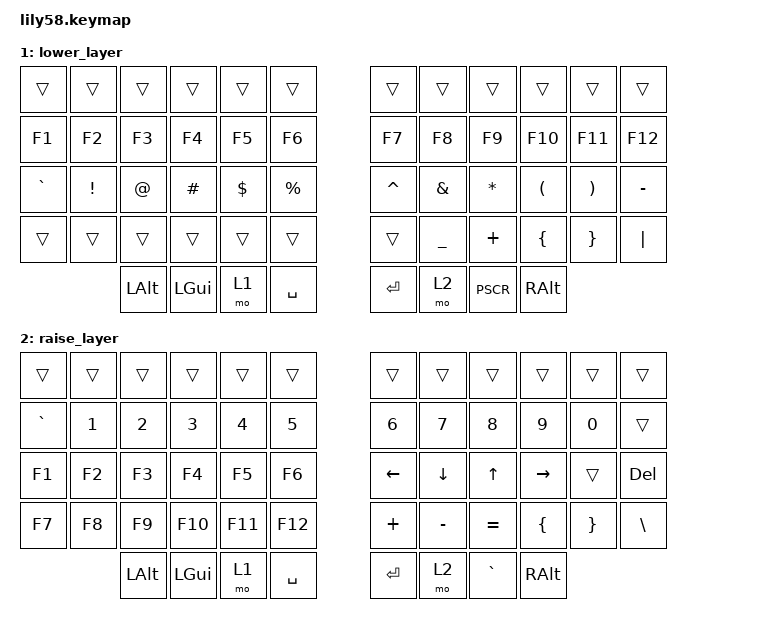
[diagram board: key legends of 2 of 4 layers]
/*
 * Copyright (c) 2020 The ZMK Contributors
 *
 * SPDX-License-Identifier: MIT
 */

#include <behaviors.dtsi>
#include <dt-bindings/zmk/keys.h>
#include <dt-bindings/zmk/bt.h>
#include <dt-bindings/zmk/ext_power.h>
#include <dt-bindings/zmk/rgb.h>

/ {
    // Activar la capa ADJUST presionando raise y lower
    conditional_layers {
        compatible = "zmk,conditional-layers";

        raise_layer {
            if-layers = <1>;
            then-layer = <3>;
        };

        lower_layer {
            if-layers = <2>;
            then-layer = <3>;
        };

        adjust_layer {
            if-layers = <1 2>;
            then-layer = <3>;
        };
    };

    keymap {
        compatible = "zmk,keymap";

        default_layer {
            /* default_layer
             * ,-----------------------------------------.                    ,-----------------------------------------.
             * | ESC  |   1  |   2  |   3  |   4  |   5  |                    |   6  |   7  |   8  |   9  |   0  |BackSP|
             * |------+------+------+------+------+------|                    |------+------+------+------+------+------|
             * | Tab  |   Q  |   W  |   E  |   R  |   T  |                    |   Y  |   U  |   I  |   O  |   P  |  -   |
             * |------+------+------+------+------+------|                    |------+------+------+------+------+------|
             * |LShift|   A  |   S  |   D  |   F  |   G  |-------.    ,-------|   H  |   J  |   K  |   L  |   ;  |  '   |
             * |------+------+------+------+------+------|   [   |    |    ]  |------+------+------+------+------+------|
             * |LCTRL |   Z  |   X  |   C  |   V  |   B  |-------|    |-------|   N  |   M  |   ,  |   .  |   /  |RShift|
             * `-----------------------------------------/       /     \      \-----------------------------------------'
             *                   | LAlt | LGUI |LOWER | /Space  /       \Enter \  |RAISE |  `   | RALT |
             *                   |      |      |      |/       /         \      \ |      |      |      |
             *                   `----------------------------'           '------''--------------------'
             */
            bindings = <
            &kp ESC   &kp N1 &kp N2 &kp N3   &kp N4   &kp N5                     &kp N6 &kp N7   &kp N8    &kp N9  &kp N0   &kp BSPC
            &kp TAB   &kp Q  &kp W  &kp E    &kp R    &kp T                      &kp Y  &kp U    &kp I     &kp O   &kp P    &kp MINUS
            &kp LSHFT &kp A  &kp S  &kp D    &kp F    &kp G                      &kp H  &kp J    &kp K     &kp L   &kp SEMI &kp SQT
            &kp LCTRL &kp Z  &kp X  &kp C    &kp V    &kp B  &kp LBRC    &kp RBRC &kp N  &kp M    &kp COMMA &kp DOT &kp FSLH &kp RSHFT
            &kp LALT &kp LGUI &mo 1  &kp SPACE  &kp RET  &mo 2  &kp GRAVE &kp RALT
            >;

            sensor-bindings = <&inc_dec_kp C_VOL_UP C_VOL_DN &inc_dec_kp PG_UP PG_DN>;
        };

        lower_layer {
            /* LOWER
             * ,-----------------------------------------.                    ,-----------------------------------------.
             * |      |      |      |      |      |      |                    |      |      |      |      |      |      |
             * |------+------+------+------+------+------|                    |------+------+------+------+------+------|
             * |  F1  |  F2  |  F3  |  F4  |  F5  |  F6  |                    |  F7  |  F8  |  F9  | F10  | F11  | F12  |
             * |------+------+------+------+------+------|                    |------+------+------+------+------+------|
             * |   `  |   !  |   @  |   #  |   $  |   %  |-------.    ,-------|   ^  |   &  |   *  |   (  |   )  |   -  |
             * |------+------+------+------+------+------|   [   |    |    ]  |------+------+------+------+------+------|
             * |      |      |      |      |      |      |-------|    |-------|      |   _  |   +  |   {  |   }  |   |  |
             * `-----------------------------------------/       /     \      \-----------------------------------------'
             *                   | LAlt | LGUI |LOWER | /Space  /       \Enter \  |RAISE |PSCR  | RALT |
             *                   |      |      |      |/       /         \      \ |      |      |      |
             *                   `----------------------------'           '------''--------------------'
             */
            bindings = <
            &trans &trans &trans &trans &trans &trans                 &trans &trans &trans &trans &trans &trans
            &kp F1 &kp F2 &kp F3 &kp F4 &kp F5 &kp F6                 &kp F7 &kp F8 &kp F9 &kp F10 &kp F11 &kp F12
            &kp GRAVE &kp EXCL &kp AT &kp HASH &kp DOLLAR &kp PRCNT   &kp CARET &kp AMPS &kp ASTRK &kp LPAR &kp RPAR &kp MINUS
            &trans &trans &trans &trans &trans &trans                 &trans &kp UNDER &kp PLUS &kp LBRC &kp RBRC &kp PIPE
            &kp LALT &kp LGUI &mo 1 &kp SPACE &kp RET &mo 2 &kp PSCR &kp RALT
            >;

            sensor-bindings = <&inc_dec_kp C_VOL_UP C_VOL_DN &inc_dec_kp PG_UP PG_DN>;
        };

        raise_layer {
            /* RAISE
             * ,-----------------------------------------.                    ,-----------------------------------------.
             * |      |      |      |      |      |      |                    |      |      |      |      |      |      |
             * |------+------+------+------+------+------|                    |------+------+------+------+------+------|
             * |   `  |   1  |   2  |   3  |   4  |   5  |                    |   6  |   7  |   8  |   9  |   0  |      |
             * |------+------+------+------+------+------|                    |------+------+------+------+------+------|
             * |  F1  |  F2  |  F3  |  F4  |  F5  |  F6  |-------.    ,-------|Left  | Down | Up   |Right |      |del   |
             * |------+------+------+------+------+------|   [   |    |    ]  |------+------+------+------+------+------|
             * |  F7  |  F8  |  F9  | F10  | F11  | F12  |-------|    |-------|   +  |   -  |   =  |   [  |   ]  |   \  |
             * `-----------------------------------------/       /     \      \-----------------------------------------'
             *                   | LAlt | LGUI |LOWER | /Space  /       \Enter \  |RAISE | `    | RALT |
             *                   |      |      |      |/       /         \      \ |      |      |      |
             *                   `----------------------------'           '------''--------------------'
             */
            bindings = <
                &trans &trans &trans &trans &trans &trans                 &trans &trans &trans &trans &trans &trans
                &kp GRAVE &kp N1 &kp N2 &kp N3 &kp N4 &kp N5               &kp N6 &kp N7 &kp N8 &kp N9 &kp N0 &trans
                &kp F1 &kp F2 &kp F3 &kp F4 &kp F5 &kp F6                  &kp LEFT &kp DOWN &kp UP &kp RIGHT &trans &kp DEL
                &kp F7 &kp F8 &kp F9 &kp F10 &kp F11 &kp F12               &kp PLUS &kp MINUS &kp EQUAL &kp LBRC &kp RBRC &kp BSLH
                &kp LALT &kp LGUI &mo 1 &kp SPACE &kp RET &mo 2 &kp GRAVE &kp RALT
            >;

            sensor-bindings = <&inc_dec_kp C_VOL_UP C_VOL_DN &inc_dec_kp PG_UP PG_DN>;
        };

        adjust_layer {
            /* ADJUST
             * ,-----------------------------------------.                    ,-----------------------------------------.
             * | BTCLR| BT1  | BT2  | BT3  | BT4  | BT5  |                    |      |      |      |      |      |      |
             * |------+------+------+------+------+------|                    |------+------+------+------+------+------|
             * |EXTPWR|RGBHUD|RGBHUI|RGBSAD|RGBSAI|RGBEFF|                    |      |      |      |      |      |      |
             * |------+------+------+------+------+------|                    |------+------+------+------+------+------|
             * |      |RGBBRD|RGBBRI|      |      |      |-------.    ,-------|      |      |      |      |      |      |
             * |------+------+------+------+------+------|RGBTOG |    |       |------+------+------+------+------+------|
             * |      |      |      |      |      |      |-------|    |-------|      |      |      |      |      |      |
             * `-----------------------------------------/       /     \      \-----------------------------------------'
             *                   |      |      |      | /       /       \      \  |      |      |      |
             *                   |      |      |      |/       /         \      \ |      |      |      |
             *                   `----------------------------'           '------''--------------------'
             */
            bindings = <
                &bt BT_CLR        &bt BT_SEL 0    &bt BT_SEL 1    &bt BT_SEL 2    &bt BT_SEL 3    &bt BT_SEL 4                            &trans &trans &trans &trans &trans &trans
                &ext_power EP_TOG &rgb_ug RGB_HUD &rgb_ug RGB_HUI &rgb_ug RGB_SAD &rgb_ug RGB_SAI &rgb_ug RGB_EFF                         &trans &trans &trans &trans &trans &trans
                &trans             &rgb_ug RGB_BRD &rgb_ug RGB_BRI &trans           &trans           &trans                                   &trans &trans &trans &trans &trans &trans
                &trans             &trans           &trans           &trans           &trans           &trans            &trans &trans  &trans &trans &trans &trans &trans &trans
                &trans           &trans           &trans           &trans            &trans           &trans  &trans &trans &trans &trans
            >;

            sensor-bindings = <&inc_dec_kp C_VOL_UP C_VOL_DN>;
        };
    };
};
